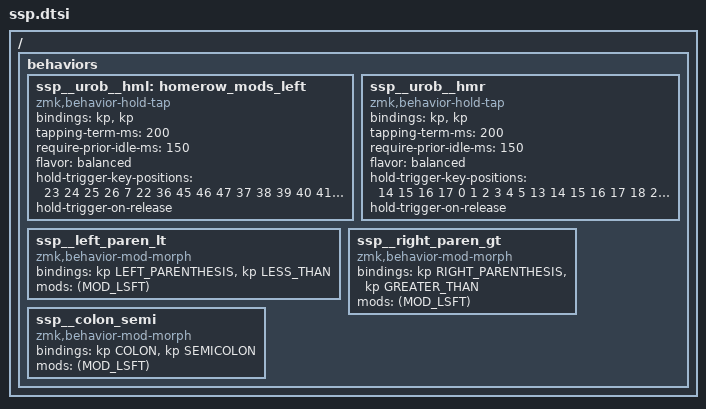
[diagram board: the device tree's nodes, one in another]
/ {
    behaviors {        ssp__urob__hml: homerow_mods_left {
            compatible = "zmk,behavior-hold-tap";
            bindings = <&kp>, <&kp>;

            #binding-cells = <2>;
            tapping-term-ms = <200>;
            require-prior-idle-ms = <150>;
            flavor = "balanced";
            hold-trigger-key-positions = <23 24 25 26 7 22 36 45 46 47 37 38 39 40 41 8 9 10 11 12 23 24 25 26 27 42 43 44>;
            hold-trigger-on-release;
        };

        ssp__urob__hmr: ssp__urob__hmr {
            compatible = "zmk,behavior-hold-tap";
            bindings = <&kp>, <&kp>;

            #binding-cells = <2>;
            tapping-term-ms = <200>;
            require-prior-idle-ms = <150>;
            flavor = "balanced";
            hold-trigger-key-positions = <14 15 16 17 0 1 2 3 4 5 13 14 15 16 17 18 28 29 30 31 32 33 42 43 44 45 46 47>;
            hold-trigger-on-release;
        };

        ssp__left_paren_lt: ssp__left_paren_lt {
            compatible = "zmk,behavior-mod-morph";
            bindings = <&kp LEFT_PARENTHESIS>, <&kp LESS_THAN>;

            #binding-cells = <0>;
            mods = <(MOD_LSFT)>;
        };

        ssp__right_paren_gt: ssp__right_paren_gt {
            compatible = "zmk,behavior-mod-morph";
            bindings = <&kp RIGHT_PARENTHESIS>, <&kp GREATER_THAN>;

            #binding-cells = <0>;
            mods = <(MOD_LSFT)>;
        };

        ssp__colon_semi: ssp__colon_semi {
            compatible = "zmk,behavior-mod-morph";
            bindings = <&kp COLON>, <&kp SEMICOLON>;

            #binding-cells = <0>;
            mods = <(MOD_LSFT)>;
        };    };
};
